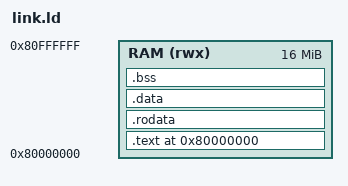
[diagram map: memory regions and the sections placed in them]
OUTPUT_ARCH(riscv)
ENTRY(_start)

MEMORY
{
    RAM (rwx) : ORIGIN = 0x80000000, LENGTH = 16M
}

SECTIONS
{
    . = ORIGIN(RAM);

    .text : {
        *(.text._start)
        *(.text .text.*)
    } > RAM

    .rodata : {
        *(.rodata .rodata.*)
    } > RAM

    .data : {
        *(.data .data.*)
    } > RAM

    .bss : {
        __bss_start = .;
        *(.bss .bss.*)
        *(COMMON)
        __tls_get_addr = .;
        __bss_end = .;
    } > RAM

    _stack_top = ORIGIN(RAM) + LENGTH(RAM);
}
